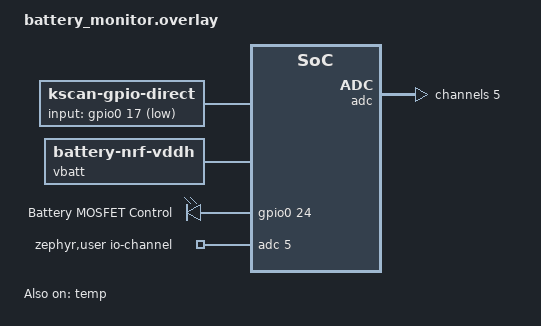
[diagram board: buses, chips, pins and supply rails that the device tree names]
/*
 * battery_monitor.overlay
 * Hardware configuration for Battery Monitor Shield (2 nice!nano setup)
 * 
 * Location: config/boards/shields/battery_monitor/battery_monitor.overlay
 * 
 * Each nice!nano monitors one cell via BAT+ pin (built-in voltage sensing)
 * Board #1: Cell 1 (BAT+ = Cell 1+, GND = Cell 1-)
 * Board #2: Cell 2 (BAT+ = Cell 2+, GND = Cell 1+)
 */

/ {
    chosen {
        zmk,battery = &vbatt;
        zmk,kscan = &kscan0;
        zmk,matrix_transform = &default_transform;
    };

   /*
 * Matrix transform - 100 positions (0-99)
 * Position 0: Physical button on P0.17
 * Position 1-98: Virtual (unused)
 * Position 99: Virtual bootloader trigger
 */
default_transform: keymap_transform_0 {
    compatible = "zmk,matrix-transform";
    columns = <100>;  // ⭐ THAY ĐỔI: 1 → 100
    rows = <1>;
    map = 
      <  0 1 2 3 4 5 6 7 8 9
        10 11 12 13 14 15 16 17 18 19
        20 21 22 23 24 25 26 27 28 29
        30 31 32 33 34 35 36 37 38 39
        40 41 42 43 44 45 46 47 48 49
        50 51 52 53 54 55 56 57 58 59
        60 61 62 63 64 65 66 67 68 69
        70 71 72 73 74 75 76 77 78 79
        80 81 82 83 84 85 86 87 88 89
        90 91 92 93 94 95 96 97 98 99
    >;  // ⭐ THÊM MAP 0-99
};

/*
 * Kscan - chỉ có 1 physical button nhưng khai báo 100 virtual positions
 */
kscan0: kscan {
    compatible = "zmk,kscan-gpio-direct";
    label = "KSCAN";
    input-gpios = 
        <&gpio0 17 (GPIO_ACTIVE_LOW | GPIO_PULL_UP)>  // Position 0 - physical
        // Positions 1-99 không có GPIO (virtual)
    ;
    debounce-period = <10>;
};



    /*
     * Battery voltage sensing using nice!nano built-in divider
     * Each board automatically monitors its connected cell (3.0-4.2V)
     * No external voltage divider needed!
     */
    vbatt: vbatt {
        compatible = "zmk,battery-nrf-vddh";
    };

    /*
     * MOSFET control for battery power switching
     * GPIO P0.24 (D5 pin on nice!nano) controls MOSFET gate
     */
    mosfet {
        compatible = "gpio-leds";
        mosfet_ctrl: mosfet_control {
            gpios = <&gpio0 24 GPIO_ACTIVE_HIGH>;
            label = "Battery MOSFET Control";
        };
    };
};

/*
 * Enable GPIO
 */
&gpio0 {
    status = "okay";
};

/*
 * Enable ADC for battery monitoring
 */
&adc {
    status = "okay";
};

/*
 * Enable temperature sensor (nRF52840 internal)
 */
&temp {
    status = "okay";
};



 / {
    zephyr,user {
        io-channels = <&adc 5>; 
    };
};

&adc {
    #address-cells = <1>;
    #size-cells = <0>;
    status = "okay";

    channel@5 {  // ✅ AIN7 channel
        reg = <5>;  // ✅ ADC channel 7
        zephyr,gain = "ADC_GAIN_1_6";
        zephyr,reference = "ADC_REF_INTERNAL";
        zephyr,acquisition-time = <ADC_ACQ_TIME_DEFAULT>;
        zephyr,input-positive = <NRF_SAADC_AIN5>;  
        zephyr,resolution = <12>;
    };
};
